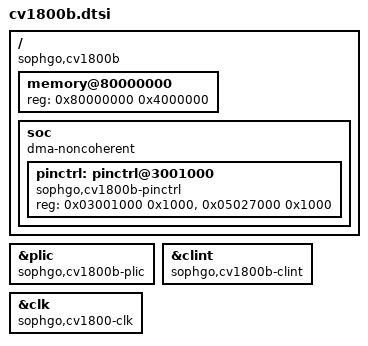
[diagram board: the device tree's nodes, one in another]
// SPDX-License-Identifier: (GPL-2.0 OR MIT)
/*
 * Copyright (C) 2023 Jisheng Zhang <jszhang@kernel.org>
 */

#define SOC_PERIPHERAL_IRQ(nr)	((nr) + 16)

#include <dt-bindings/pinctrl/pinctrl-cv1800b.h>
#include "cv18xx.dtsi"
#include "cv18xx-cpu-intc.dtsi"

/ {
	compatible = "sophgo,cv1800b";

	memory@80000000 {
		device_type = "memory";
		reg = <0x80000000 0x4000000>;
	};

	soc {
		dma-noncoherent;

		pinctrl: pinctrl@3001000 {
			compatible = "sophgo,cv1800b-pinctrl";
			reg = <0x03001000 0x1000>,
			      <0x05027000 0x1000>;
			reg-names = "sys", "rtc";
		};
	};
};

&plic {
	compatible = "sophgo,cv1800b-plic", "thead,c900-plic";
};

&clint {
	compatible = "sophgo,cv1800b-clint", "thead,c900-clint";
};

&clk {
	compatible = "sophgo,cv1800-clk";
};
